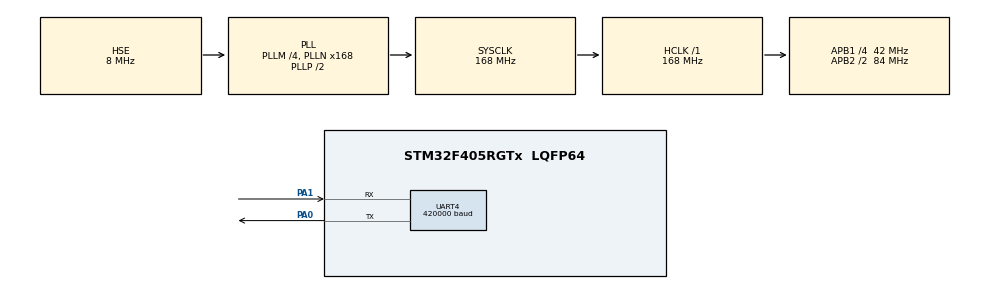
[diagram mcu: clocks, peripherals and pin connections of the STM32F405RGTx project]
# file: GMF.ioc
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Dma.Request0=UART4_RX
Dma.Request1=UART4_TX
Dma.UART4_RX.0.Direction=DMA_PERIPH_TO_MEMORY
Dma.UART4_RX.0.FIFOMode=DMA_FIFOMODE_DISABLE
Dma.UART4_RX.0.Instance=DMA1_Stream2
Dma.UART4_RX.0.MemDataAlignment=DMA_MDATAALIGN_BYTE
Dma.UART4_RX.0.MemInc=DMA_MINC_ENABLE
Dma.UART4_RX.0.Mode=DMA_CIRCULAR
Dma.UART4_RX.0.PeriphDataAlignment=DMA_PDATAALIGN_BYTE
Dma.UART4_RX.0.PeriphInc=DMA_PINC_DISABLE
Dma.UART4_RX.0.Priority=DMA_PRIORITY_LOW
Dma.UART4_TX.1.Direction=DMA_MEMORY_TO_PERIPH
Dma.UART4_TX.1.FIFOMode=DMA_FIFOMODE_DISABLE
Dma.UART4_TX.1.Instance=DMA1_Stream4
Dma.UART4_TX.1.MemDataAlignment=DMA_MDATAALIGN_BYTE
Dma.UART4_TX.1.MemInc=DMA_MINC_ENABLE
Dma.UART4_TX.1.Mode=DMA_CIRCULAR
Dma.UART4_TX.1.PeriphDataAlignment=DMA_PDATAALIGN_BYTE
Dma.UART4_TX.1.PeriphInc=DMA_PINC_DISABLE
Dma.UART4_TX.1.Priority=DMA_PRIORITY_LOW
Mcu.Family=STM32F4
Mcu.Name=STM32F405RGTx
Mcu.Package=LQFP64
NVIC.DMA1_Stream2_IRQn=true\:0\:0\:false\:false\:true\:false\:true
NVIC.DMA1_Stream4_IRQn=true\:0\:0\:false\:false\:true\:false\:true
NVIC.PriorityGroup=NVIC_PRIORITYGROUP_4
NVIC.UART4_IRQn=true\:0\:0\:false\:false\:true\:true\:true
PA0-WKUP.Mode=Asynchronous
PA0-WKUP.Signal=UART4_TX
PA1.Mode=Asynchronous
PA1.Signal=UART4_RX
PH0-OSC_IN.Mode=HSE-External-Oscillator
PH0-OSC_IN.Signal=RCC_OSC_IN
PH1-OSC_OUT.Mode=HSE-External-Oscillator
PH1-OSC_OUT.Signal=RCC_OSC_OUT
ProjectManager.HeapSize=0x200
ProjectManager.StackSize=0x400
ProjectManager.TargetToolchain=STM32CubeIDE
RCC.48MHZClocksFreq_Value=84000000
RCC.AHBFreq_Value=168000000
RCC.APB1CLKDivider=RCC_HCLK_DIV4
RCC.APB1Freq_Value=42000000
RCC.APB1TimFreq_Value=84000000
RCC.APB2CLKDivider=RCC_HCLK_DIV2
RCC.APB2Freq_Value=84000000
RCC.APB2TimFreq_Value=168000000
RCC.CortexFreq_Value=168000000
RCC.HCLKFreq_Value=168000000
RCC.HSE_VALUE=8000000
RCC.HSI_VALUE=16000000
RCC.LSE_VALUE=32768
RCC.PLLM=4
RCC.PLLN=168
RCC.PLLSourceVirtual=RCC_PLLSOURCE_HSE
RCC.SYSCLKFreq_VALUE=168000000
RCC.SYSCLKSource=RCC_SYSCLKSOURCE_PLLCLK
RCC.VCOOutputFreq_Value=336000000
UART4.BaudRate=420000
UART4.VirtualMode=Asynchronous
board=custom

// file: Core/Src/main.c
/* USER CODE BEGIN Header */
/**
  ******************************************************************************
  * @file           : main.c
  * @brief          : Main program body
  ******************************************************************************
  * @attention
  *
  * <h2><center>&copy; Copyright (c) 2022 STMicroelectronics.
  * All rights reserved.</center></h2>
  *
  * This software component is licensed by ST under BSD 3-Clause license,
  * the "License"; You may not use this file except in compliance with the
  * License. You may obtain a copy of the License at:
  *                        opensource.org/licenses/BSD-3-Clause
  *
  ******************************************************************************
  */
/* USER CODE END Header */
#include "main.h"
#include "dma.h"
#include "usart.h"
#include "gpio.h"

/* USER CODE BEGIN Includes */
#include "stdio.h"
#include "string.h"
/* USER CODE END Includes */

/* USER CODE BEGIN PV */
uint8_t serial_byte;
uint8_t serial_ptr;
uint8_t serial_buf[50];
uint8_t serial_buf_channels[25];
uint8_t serial_buf_changed[25];
uint8_t serial_buf_lq[25];
int8_t clear_buf = 0;
uint8_t sync = 0;

uint32_t unsync_rate = 0;
uint16_t wait_to_sync = 0;

uint16_t channels[16];
uint16_t sync_val = 26;
uint8_t frame_size;
/* USER CODE END PV */

void SystemClock_Config(void);

int main(void)
{

  /* MCU Configuration--------------------------------------------------------*/

  /* Reset of all peripherals, Initializes the Flash interface and the Systick. */
  HAL_Init();

  /* Configure the system clock */
  SystemClock_Config();

  /* Initialize all configured peripherals */
  MX_GPIO_Init();
  MX_DMA_Init();
  MX_UART4_Init();
  /* USER CODE BEGIN 2 */
  HAL_UART_Receive_DMA(&huart4, &serial_byte, 1);
  /* USER CODE END 2 */

  /* Infinite loop */
  /* USER CODE BEGIN WHILE */
  while (1)
  {
	  if(clear_buf){
		  clear_buf = 0;
		  memset(serial_buf_changed, 0, 25);
	  }
    /* USER CODE END WHILE */

  }
}

void SystemClock_Config(void)
{
  RCC_OscInitTypeDef RCC_OscInitStruct = {0};
  RCC_ClkInitTypeDef RCC_ClkInitStruct = {0};

  /** Configure the main internal regulator output voltage
  */
  __HAL_RCC_PWR_CLK_ENABLE();
  __HAL_PWR_VOLTAGESCALING_CONFIG(PWR_REGULATOR_VOLTAGE_SCALE1);
  /** Initializes the RCC Oscillators according to the specified parameters
  * in the RCC_OscInitTypeDef structure.
  */
  RCC_OscInitStruct.OscillatorType = RCC_OSCILLATORTYPE_HSE;
  RCC_OscInitStruct.HSEState = RCC_HSE_ON;
  RCC_OscInitStruct.PLL.PLLState = RCC_PLL_ON;
  RCC_OscInitStruct.PLL.PLLSource = RCC_PLLSOURCE_HSE;
  RCC_OscInitStruct.PLL.PLLM = 4;
  RCC_OscInitStruct.PLL.PLLN = 168;
  RCC_OscInitStruct.PLL.PLLP = RCC_PLLP_DIV2;
  RCC_OscInitStruct.PLL.PLLQ = 4;
  if (HAL_RCC_OscConfig(&RCC_OscInitStruct) != HAL_OK)
  {
    Error_Handler();
  }
  /** Initializes the CPU, AHB and APB buses clocks
  */
  RCC_ClkInitStruct.ClockType = RCC_CLOCKTYPE_HCLK|RCC_CLOCKTYPE_SYSCLK
                              |RCC_CLOCKTYPE_PCLK1|RCC_CLOCKTYPE_PCLK2;
  RCC_ClkInitStruct.SYSCLKSource = RCC_SYSCLKSOURCE_PLLCLK;
  RCC_ClkInitStruct.AHBCLKDivider = RCC_SYSCLK_DIV1;
  RCC_ClkInitStruct.APB1CLKDivider = RCC_HCLK_DIV4;
  RCC_ClkInitStruct.APB2CLKDivider = RCC_HCLK_DIV2;

  if (HAL_RCC_ClockConfig(&RCC_ClkInitStruct, FLASH_LATENCY_5) != HAL_OK)
  {
    Error_Handler();
  }
}

/* USER CODE BEGIN 4 */
void HAL_UART_RxCpltCallback(UART_HandleTypeDef *huart){
	if(serial_ptr > 49){
		serial_ptr = 0;
		sync = 0;
		memset(serial_buf, 0, 50);
		unsync_rate++;
	}

	if(serial_byte == 0xc8 && sync == 0){
		memset(serial_buf, 0, 50);
		serial_buf[serial_ptr] = serial_byte;
		serial_ptr = 1;
		sync = 1;
		return;
	}

	if(sync == 1){
		if(serial_byte > 50){
			serial_ptr = 0;
			sync = 0;
			return;
		}
		frame_size = serial_byte;
		serial_buf[serial_ptr] = serial_byte;
		serial_ptr++;
		sync = 2;
		return;
	}

	if(sync == 2){
		serial_buf[serial_ptr] = serial_byte;
		serial_ptr++;
		if(serial_ptr >= frame_size + 1){
			sync = 0;
			serial_ptr = 0;
//			frame_size = 0;

			if(frame_size == 24 && serial_buf[2] == 0x16){
				for(int i = 0; i < 25; i++){
					if(serial_buf_channels[i] == serial_buf[i]) continue;

					for(int bit = 0; bit < 8; bit++){
						if(((serial_buf_channels[i] >> bit) & 1) != ((serial_buf[i] >> bit) & 1)) serial_buf_changed[i] |= 1 << bit;
					}
				}
				memcpy(serial_buf_channels, serial_buf, 25);
			//11 bit
			//analog
				channels[0] = (serial_buf[3] + ((serial_buf[4] & 0b111) << 8)) >> 0;
				channels[1] = (serial_buf[4] >> 3) + (((serial_buf[5] & 0b111111) << 5) >> 0);
				channels[2] = (serial_buf[5] >> 6) + ((serial_buf[6] & 0xff) << 2) + ((serial_buf[7] & 0b1) << 10);
				channels[3] = (serial_buf[7] >> 1) + ((serial_buf[8] & 0b1111) << 7);

//				channels[4] = (serial_buf[8] >> 4) + ((serial_buf[9] & 0b1111111) << 4);
//				channels[5] = (serial_buf[9] >> 7) + (serial_buf[10] << 1) + ((serial_buf[11] & 0b11) << 9);
//				channels[6] = (serial_buf[11] >> 3) + ((serial_buf[12] & 0b11111) << 5);
//				channels[7] = (serial_buf[13] >> 5) + (serial_buf[14] << 3);		//bit 7 dari byte[12] dan

//				channels[8] = serial_buf[15] + ((serial_buf[16] & 0b111) << 8);
//				channels[9] = (serial_buf[16] >> 3) + ((serial_buf[17] & 0b111111) << 5);
//				channels[10] = (serial_buf[17] >> 6) + ((serial_buf[18] & 0xff) << 2) + ((serial_buf[19] & 0b1) << 10);
//				channels[11] = (serial_buf[19] >> 1) + ((serial_buf[20] & 0b1111) << 7);
//
//				channels[12] = (serial_buf[20] >> 4) + ((serial_buf[21] & 0b1111111) << 4);
//				channels[13] = (serial_buf[9] >> 7) + (serial_buf[10] << 1) + ((serial_buf[11] & 0b11) << 9);
//				channels[14] = (serial_buf[11] >> 2) + ((serial_buf[12] & 0b11111) << 6);
//				channels[15] = (serial_buf[13] >> 5) + (serial_buf[14] << 3);

			//switches
				//sw E
				channels[4] = (serial_buf[8] >> 4) + ((serial_buf[9] & 0b1111111) << 4);

				//sw F
				channels[5] = (serial_buf[9] >> 7) + (serial_buf[10] << 1) + ((serial_buf[11] & 0b11) << 9);

				//sw B
				channels[6] = (serial_buf[11] >> 2) + ((serial_buf[12] & 0b11111) << 6);

				//sw C
				channels[7] = (serial_buf[12] >> 5) + ((serial_buf[13] << 3));

				//sw(button) A
				channels[8] = (serial_buf[14]) + ((serial_buf[15] & 0b111) << 8);

				//sw(button) D
				channels[9] = (serial_buf[15] >> 3) + ((serial_buf[16] & 0b111111) << 5);

				//sw(button) G
				channels[10] = ((serial_buf[16]) >> 6) + (serial_buf[17] << 2) + ((serial_buf[18] & 1) << 10);

				//sw(button) H
				channels[11] = (serial_buf[18] >> 1) + ((serial_buf[19] & 0b1111) << 7);

				//potensio S1 (kiri)
				channels[12] = (serial_buf[19] >> 4) + ((serial_buf[20] & 0b1111111) << 4);

				//potensio S2 (kanan)
				//ga ada berubah??

//				channels[6] = (serial_buf[11] >> 3) + ((serial_buf[12] & 0b11111) << 5);
//				channels[7] = (serial_buf[12] >> 6) + (serial_buf[13] << 2);
//				channels[8] = (serial_buf[14]) + (serial_buf[15] & 0b111) << 8;
			}

			if(serial_buf[2] == 0x14){
				memcpy(serial_buf_lq, serial_buf, serial_buf[1] + 1);
			}
		}

	}
}

void HAL_TIM_PeriodElapsedCallback(TIM_HandleTypeDef* htim){
   	if(htim->Instance == TIM3){
   		tim_called++;
   	}
}
/* USER CODE END 4 */

void Error_Handler(void)
{
  __disable_irq();
  while (1)
  {
  }
}

/************************ (C) COPYRIGHT STMicroelectronics *****END OF FILE****/
